# PIC32MK1024GPL100 register map
Vendor: Microchip
Registers are 32-bit, read-write, no defined reset value unless marked. A register's access mark holds for its fields unless they carry their own. Addresses are absolute, and some are shared; only a register's first bit layout is shown; [hi:lo] are bit positions; {n}, {i} and the like mark numbered series; 'fields as' and 'values as' point back to an identical list.

## USB2
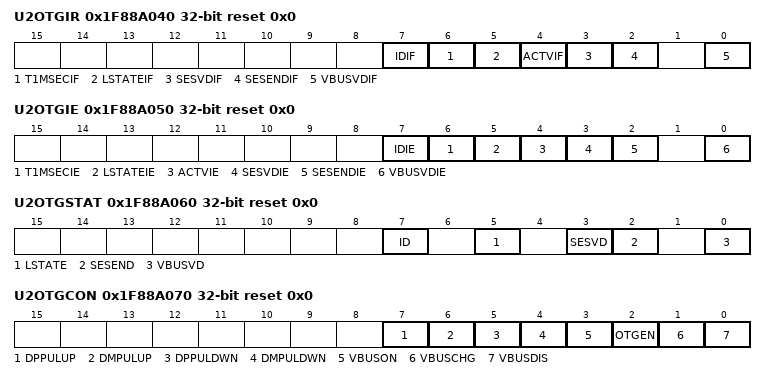
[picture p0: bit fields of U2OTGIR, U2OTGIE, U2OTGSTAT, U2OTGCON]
0x1F88A040 U2OTGIR reset 0x0
  [7] IDIF, [6] T1MSECIF, [5] LSTATEIF, [4] ACTVIF, [3] SESVDIF, [2] SESENDIF, [0] VBUSVDIF
0x1F88A050 U2OTGIE reset 0x0
  [7] IDIE, [6] T1MSECIE, [5] LSTATEIE, [4] ACTVIE, [3] SESVDIE, [2] SESENDIE, [0] VBUSVDIE
0x1F88A060 U2OTGSTAT reset 0x0
  [7] ID, [5] LSTATE, [3] SESVD, [2] SESEND, [0] VBUSVD
0x1F88A070 U2OTGCON reset 0x0
  [7] DPPULUP, [6] DMPULUP, [5] DPPULDWN, [4] DMPULDWN, [3] VBUSON, [2] OTGEN, [1] VBUSCHG, [0] VBUSDIS
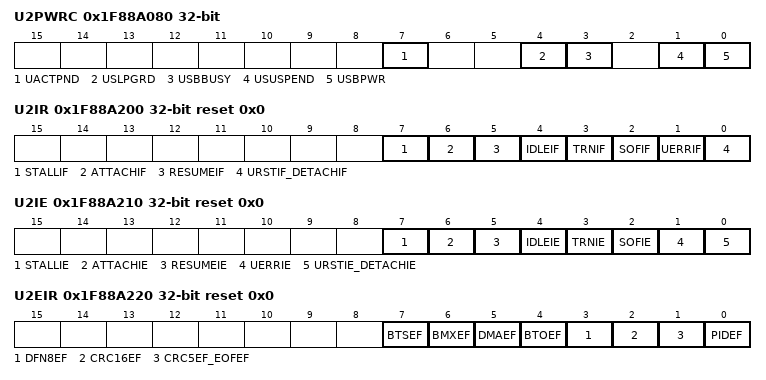
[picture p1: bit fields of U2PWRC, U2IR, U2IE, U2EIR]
0x1F88A080 U2PWRC — (power-on value ------------------------0--0x-00)
  [7] UACTPND ro, [4] USLPGRD, [3] USBBUSY, [1] USUSPEND, [0] USBPWR
0x1F88A200 U2IR reset 0x0
  [7] STALLIF, [6] ATTACHIF, [5] RESUMEIF, [4] IDLEIF, [3] TRNIF, [2] SOFIF, [1] UERRIF, [0] URSTIF_DETACHIF
0x1F88A210 U2IE reset 0x0
  [7] STALLIE, [6] ATTACHIE, [5] RESUMEIE, [4] IDLEIE, [3] TRNIE, [2] SOFIE, [1] UERRIE, [0] URSTIE_DETACHIE
0x1F88A220 U2EIR reset 0x0
  [7] BTSEF, [6] BMXEF, [5] DMAEF, [4] BTOEF, [3] DFN8EF, [2] CRC16EF, [1] CRC5EF_EOFEF, [0] PIDEF
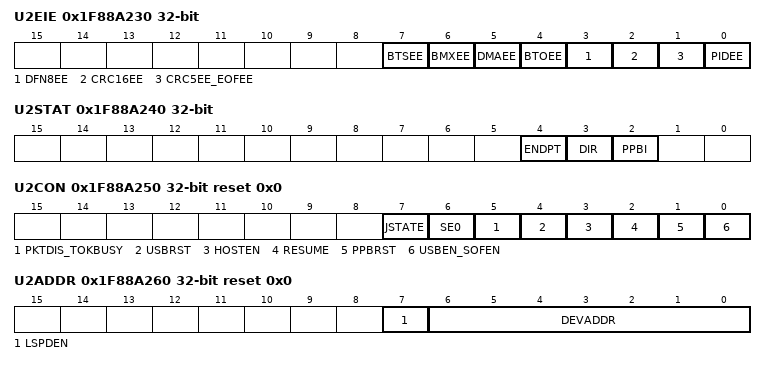
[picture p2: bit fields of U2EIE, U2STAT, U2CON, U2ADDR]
0x1F88A230 U2EIE — (power-on value ------------------------0000000x)
  [7] BTSEE, [6] BMXEE, [5] DMAEE, [4] BTOEE, [3] DFN8EE, [2] CRC16EE, [1] CRC5EE_EOFEE, [0] PIDEE
0x1F88A240 U2STAT ro
  [4] ENDPT, [3] DIR, [2] PPBI
0x1F88A250 U2CON reset 0x0
  [7] JSTATE, [6] SE0, [5] PKTDIS_TOKBUSY, [4] USBRST, [3] HOSTEN, [2] RESUME, [1] PPBRST, [0] USBEN_SOFEN
0x1F88A260 U2ADDR reset 0x0
  [7] LSPDEN, [6:0] DEVADDR
0x1F88A270 U2BDTP1 reset 0x0
  [7:1] BDTPTRL
0x1F88A280 U2FRML ro
  [7:0] FRML
0x1F88A290 U2FRMH ro
  [2:0] FRMH
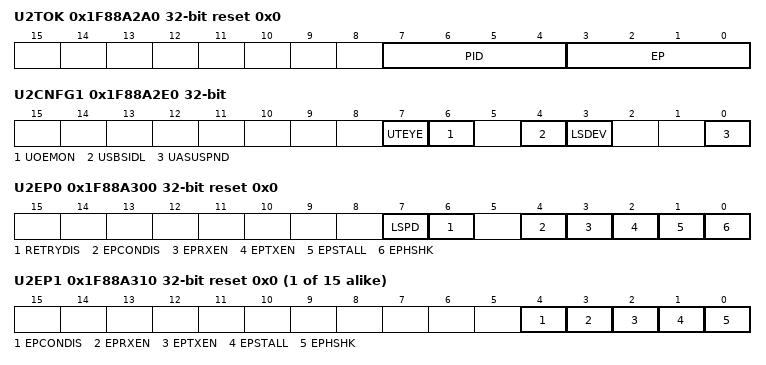
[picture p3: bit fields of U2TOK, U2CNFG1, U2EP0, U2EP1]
0x1F88A2A0 U2TOK reset 0x0
  [7:4] PID, [3:0] EP
0x1F88A2B0 U2SOF reset 0x0
  [7:0] CNT
0x1F88A2C0 U2BDTP2 reset 0x0
  [7:0] BDTPTRH
0x1F88A2D0 U2BDTP3 reset 0x0
  [7:0] BDTPTRU
0x1F88A2E0 U2CNFG1 — (power-on value ------------------------xxxxx00x)
  [7] UTEYE, [6] UOEMON, [4] USBSIDL, [3] LSDEV, [0] UASUSPND
0x1F88A300 U2EP0 reset 0x0
  [7] LSPD, [6] RETRYDIS, [4] EPCONDIS, [3] EPRXEN, [2] EPTXEN, [1] EPSTALL, [0] EPHSHK
{0x1F88A300+0x10*i} U2EP{i} reset 0x0 (i=1..15)
  [4] EPCONDIS, [3] EPRXEN, [2] EPTXEN, [1] EPSTALL, [0] EPHSHK

## RTCC
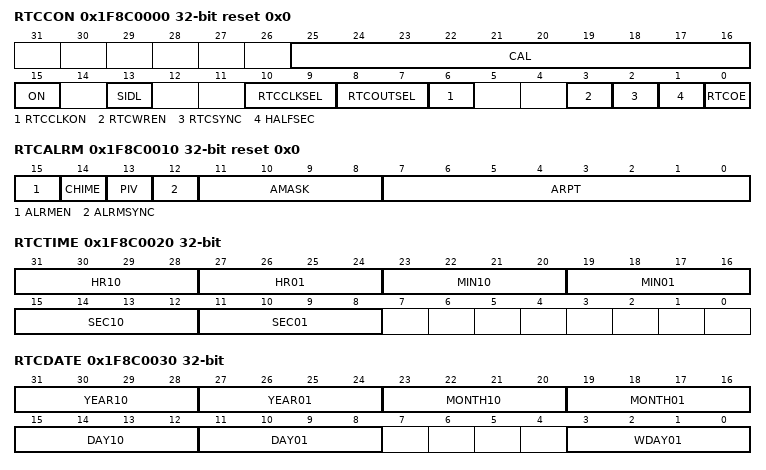
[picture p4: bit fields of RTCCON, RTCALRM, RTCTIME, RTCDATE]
0x1F8C0000 RTCCON reset 0x0
  [25:16] CAL, [15] ON, [13] SIDL, [10:9] RTCCLKSEL, [8:7] RTCOUTSEL, [6] RTCCLKON, [3] RTCWREN, [2] RTCSYNC ro, [1] HALFSEC ro, [0] RTCOE
0x1F8C0010 RTCALRM reset 0x0
  [15] ALRMEN, [14] CHIME, [13] PIV, [12] ALRMSYNC, [11:8] AMASK, [7:0] ARPT
0x1F8C0020 RTCTIME — (power-on value 000xxxxxxxxxxxxx0xxxxxxx--------)
  [31:28] HR10, [27:24] HR01, [23:20] MIN10, [19:16] MIN01, [15:12] SEC10, [11:8] SEC01
0x1F8C0030 RTCDATE — (power-on value xxxxxxxx000xxxxx00xxxxxx----0xxx)
  [31:28] YEAR10, [27:24] YEAR01, [23:20] MONTH10, [19:16] MONTH01, [15:12] DAY10, [11:8] DAY01, [3:0] WDAY01
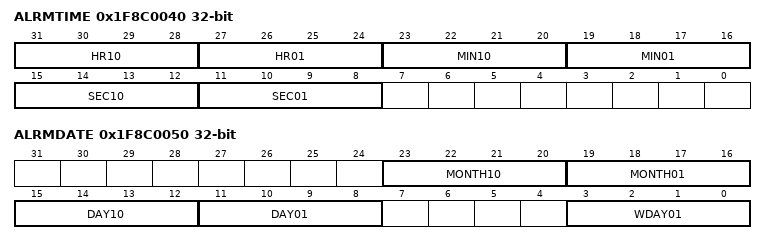
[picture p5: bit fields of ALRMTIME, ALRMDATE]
0x1F8C0040 ALRMTIME — (power-on value 000xxxxx0xxxxxxx0xxxxxxx--------)
  fields as RTCTIME
0x1F8C0050 ALRMDATE — (power-on value --------000xxxxx00xxxxxx----0xxx)
  [23:20] MONTH10, [19:16] MONTH01, [15:12] DAY10, [11:8] DAY01, [3:0] WDAY01

## lpwr_deep_sleep_ctrl
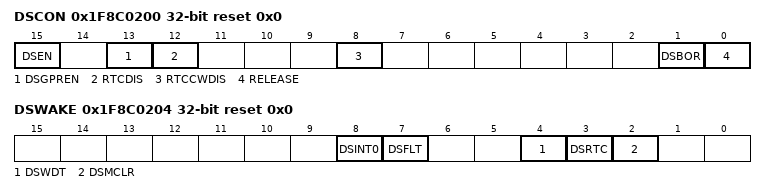
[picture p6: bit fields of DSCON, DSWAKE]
0x1F8C0200 DSCON reset 0x0
  [15] DSEN, [13] DSGPREN, [12] RTCDIS, [8] RTCCWDIS, [1] DSBOR, [0] RELEASE
0x1F8C0204 DSWAKE reset 0x0
  [8] DSINT0, [7] DSFLT, [4] DSWDT, [3] DSRTC, [2] DSMCLR
0x1F8C0208 DSGPR0 reset 0x0
  [31:0] DSGPR
{0x1F8C020C+4i} DSGPR{i} reset 0x0 (i=1..32)
  [31:0] DSGPR

## SB
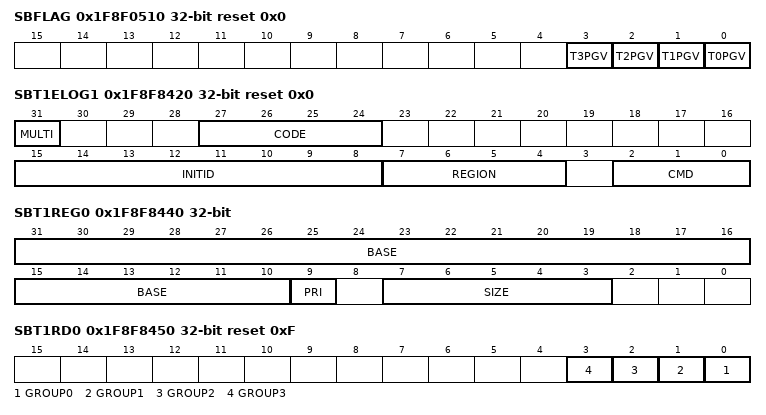
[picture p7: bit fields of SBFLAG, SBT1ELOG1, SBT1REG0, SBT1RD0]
0x1F8F0510 SBFLAG ro reset 0x0
  [n] T{n}PGV (n=0..3)
0x1F8F8420 SBT1ELOG1 reset 0x0
  [31] MULTI, [27:24] CODE, [15:8] INITID ro, [7:4] REGION ro, [2:0] CMD ro
0x1F8F8424 SBT1ELOG2 ro reset 0x0
  [1:0] GROUP
0x1F8F8428 SBT1ECON reset 0x0
  [24] ERRP
0x1F8F8430 SBT1ECLRS ro reset 0x0
  [0] CLEAR
0x1F8F8438 SBT1ECLRM ro reset 0x0
  [0] CLEAR
0x1F8F8440 SBT1REG0 — (power-on value 0000000000000000000000x-00000---)
  [31:10] BASE, [9] PRI ro, [7:3] SIZE
0x1F8F8450 SBT1RD0 reset 0xF
  [n] GROUP{n} (n=0..3)
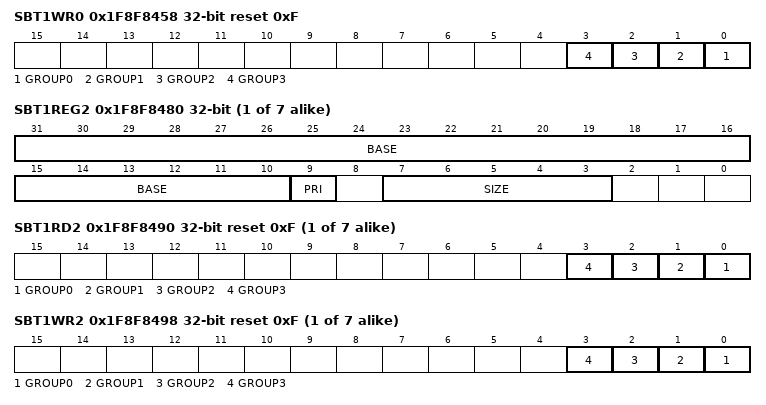
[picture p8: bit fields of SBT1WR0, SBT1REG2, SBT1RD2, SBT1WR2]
0x1F8F8458 SBT1WR0 reset 0xF
  [n] GROUP{n} (n=0..3)
{0x1F8F8440+0x20*i} SBT1REG{i} (i=2..8) — (power-on value 0000000000000000000000x-00000---)
  [31:10] BASE, [9] PRI ro, [7:3] SIZE
{0x1F8F8450+0x20*i} SBT1RD{i} reset 0xF (i=2..8)
  [n] GROUP{n} (n=0..3)
{0x1F8F8458+0x20*i} SBT1WR{i} reset 0xF (i=2..8)
  [n] GROUP{n} (n=0..3)

## DOS_EIP_00136_ssx
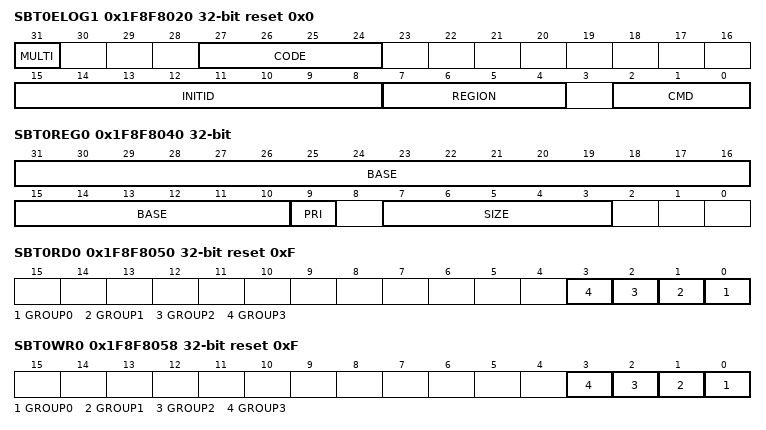
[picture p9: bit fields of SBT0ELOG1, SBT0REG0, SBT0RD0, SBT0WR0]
0x1F8F8020 SBT0ELOG1 reset 0x0
  [31] MULTI, [27:24] CODE, [15:8] INITID ro, [7:4] REGION ro, [2:0] CMD ro
0x1F8F8024 SBT0ELOG2 ro reset 0x0
  [1:0] GROUP
0x1F8F8028 SBT0ECON reset 0x0
  [24] ERRP
0x1F8F8030 SBT0ECLRS ro reset 0x0
  [0] CLEAR
0x1F8F8038 SBT0ECLRM ro reset 0x0
  [0] CLEAR
0x1F8F8040 SBT0REG0 — (power-on value 0000000000000000000000x-00000---)
  [31:10] BASE, [9] PRI ro, [7:3] SIZE
0x1F8F8050 SBT0RD0 reset 0xF
  [n] GROUP{n} (n=0..3)
0x1F8F8058 SBT0WR0 reset 0xF
  [n] GROUP{n} (n=0..3)
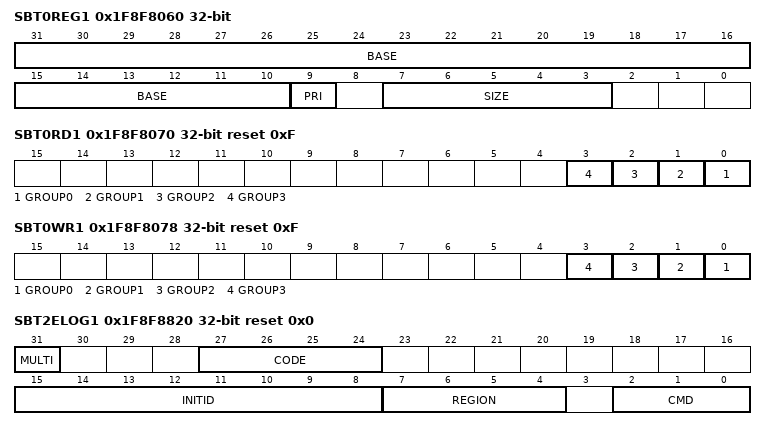
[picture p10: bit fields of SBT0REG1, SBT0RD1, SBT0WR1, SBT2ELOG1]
0x1F8F8060 SBT0REG1 — (power-on value 0000000000000000000000x-00000---)
  [31:10] BASE, [9] PRI ro, [7:3] SIZE
0x1F8F8070 SBT0RD1 reset 0xF
  [n] GROUP{n} (n=0..3)
0x1F8F8078 SBT0WR1 reset 0xF
  [n] GROUP{n} (n=0..3)
0x1F8F8820 SBT2ELOG1 reset 0x0
  fields as SBT0ELOG1
0x1F8F8824 SBT2ELOG2 ro reset 0x0
  [1:0] GROUP
0x1F8F8828 SBT2ECON reset 0x0
  [24] ERRP
0x1F8F8830 SBT2ECLRS ro reset 0x0
  [0] CLEAR
0x1F8F8838 SBT2ECLRM ro reset 0x0
  [0] CLEAR
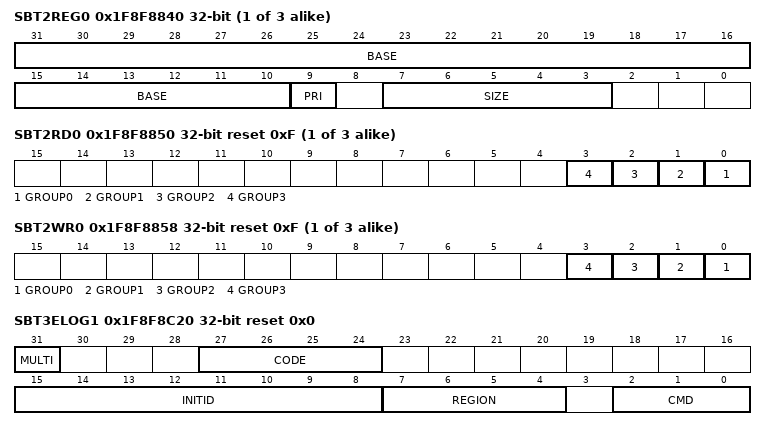
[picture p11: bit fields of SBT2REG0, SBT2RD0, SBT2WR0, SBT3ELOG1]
{0x1F8F8840+0x20*i} SBT2REG{i} (i=0..2) — (power-on value 0000000000000000000000x-00000---)
  [31:10] BASE, [9] PRI ro, [7:3] SIZE
{0x1F8F8850+0x20*i} SBT2RD{i} reset 0xF (i=0..2)
  [n] GROUP{n} (n=0..3)
{0x1F8F8858+0x20*i} SBT2WR{i} reset 0xF (i=0..2)
  [n] GROUP{n} (n=0..3)
0x1F8F8C20 SBT3ELOG1 reset 0x0
  fields as SBT0ELOG1
0x1F8F8C24 SBT3ELOG2 ro reset 0x0
  [1:0] GROUP
0x1F8F8C28 SBT3ECON reset 0x0
  [24] ERRP
0x1F8F8C30 SBT3ECLRS ro reset 0x0
  [0] CLEAR
0x1F8F8C38 SBT3ECLRM ro reset 0x0
  [0] CLEAR
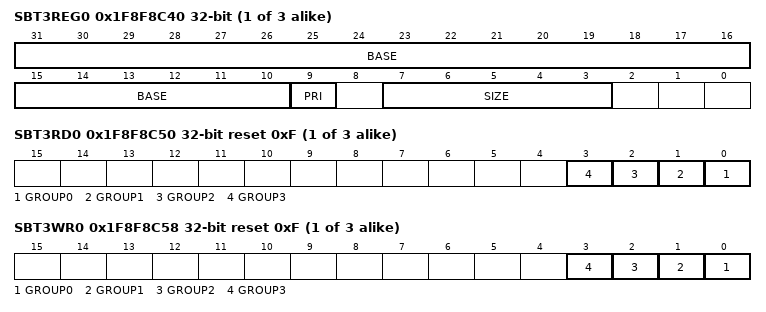
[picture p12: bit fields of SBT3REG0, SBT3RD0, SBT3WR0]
{0x1F8F8C40+0x20*i} SBT3REG{i} (i=0..2) — (power-on value 0000000000000000000000x-00000---)
  [31:10] BASE, [9] PRI ro, [7:3] SIZE
{0x1F8F8C50+0x20*i} SBT3RD{i} reset 0xF (i=0..2)
  [n] GROUP{n} (n=0..3)
{0x1F8F8C58+0x20*i} SBT3WR{i} reset 0xF (i=0..2)
  [n] GROUP{n} (n=0..3)
